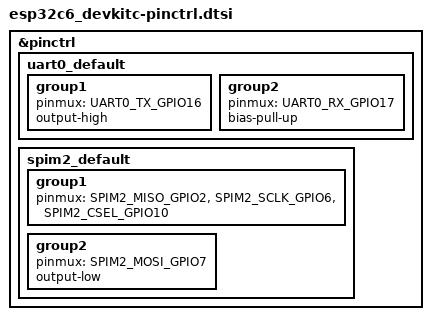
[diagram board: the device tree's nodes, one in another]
/*
 * Copyright (c) 2023 Espressif Systems (Shanghai) Co., Ltd.
 *
 * SPDX-License-Identifier: Apache-2.0
 */

#include <zephyr/dt-bindings/pinctrl/esp-pinctrl-common.h>
#include <dt-bindings/pinctrl/esp32c6-pinctrl.h>
#include <zephyr/dt-bindings/pinctrl/esp32c6-gpio-sigmap.h>

&pinctrl {

	uart0_default: uart0_default {
		group1 {
			pinmux = <UART0_TX_GPIO16>;
			output-high;
		};
		group2 {
			pinmux = <UART0_RX_GPIO17>;
			bias-pull-up;
		};
	};

	spim2_default: spim2_default {
		group1 {
			pinmux = <SPIM2_MISO_GPIO2>,
				 <SPIM2_SCLK_GPIO6>,
				 <SPIM2_CSEL_GPIO10>;
		};
		group2 {
			pinmux = <SPIM2_MOSI_GPIO7>;
			output-low;
		};
	};
};
